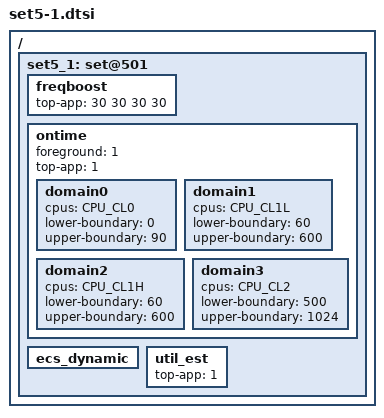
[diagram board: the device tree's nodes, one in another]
/ {
	/* camera mode - touch boost */
	set5_1: set@501 {
		/* Boosting margin applied to frequency selection */
		freqboost {	   		/* LIT MED-L MED-H BIG */
			top-app         	= < 30 30 30 30>;
		};

		/* Ontime Migration */
		ontime {
			foreground 	= <1>;
			top-app		= <1>;

			domain0 {
				cpus = CPU_CL0;
				lower-boundary = <0>;
				upper-boundary = <90>;
			};
			domain1 {
				cpus = CPU_CL1L;
				lower-boundary = <60>;
				upper-boundary = <600>;
			};
			domain2 {
				cpus = CPU_CL1H;
				lower-boundary = <60>;
				upper-boundary = <600>;
			};
			domain3 {
				cpus = CPU_CL2;
				lower-boundary = <500>;
				upper-boundary = <1024>;
			};
		};

		ecs_dynamic { };

		util_est {
			top-app	= <1>;
		};
	};
};
